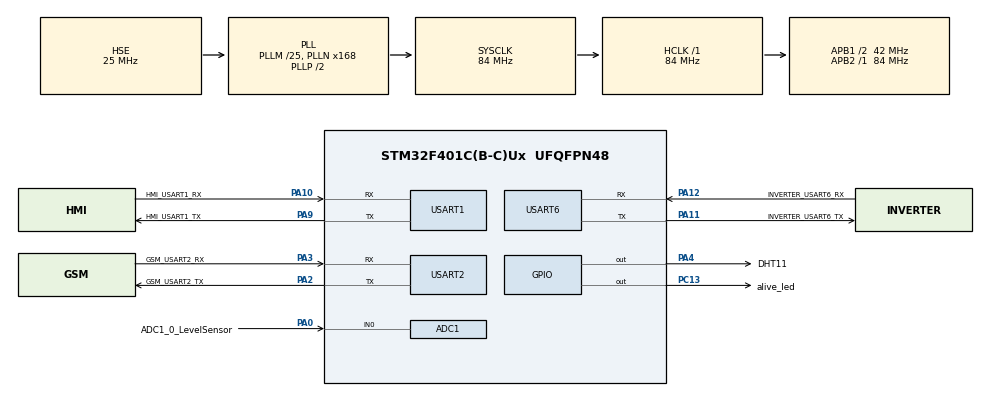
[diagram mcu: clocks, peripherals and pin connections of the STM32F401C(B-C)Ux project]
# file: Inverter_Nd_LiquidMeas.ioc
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ADC1.Channel-0\#ChannelRegularConversion=ADC_CHANNEL_0
ADC1.ContinuousConvMode=DISABLE
ADC1.NbrOfConversionFlag=1
ADC1.Rank-0\#ChannelRegularConversion=1
ADC1.SamplingTime-0\#ChannelRegularConversion=ADC_SAMPLETIME_480CYCLES
ADC1.master=1
FREERTOS.Tasks01=defaultTask,24,128,StartDefaultTask,Default,NULL,Dynamic,NULL,NULL
FREERTOS.configENABLE_FPU=1
FREERTOS.configTIMER_TASK_PRIORITY=55
FREERTOS.configTOTAL_HEAP_SIZE=30000
FREERTOS.configUSE_NEWLIB_REENTRANT=1
FREERTOS.configUSE_OS2_EVENTFLAGS_FROM_ISR=0
FREERTOS.configUSE_OS2_MUTEX=0
FREERTOS.configUSE_OS2_THREAD_ENUMERATE=0
FREERTOS.configUSE_OS2_THREAD_FLAGS=0
FREERTOS.configUSE_OS2_THREAD_SUSPEND_RESUME=0
FREERTOS.configUSE_OS2_TIMER=0
Mcu.Family=STM32F4
Mcu.Name=STM32F401C(B-C)Ux
Mcu.Package=UFQFPN48
Mcu.UserConstants=HMI_USART1,$$_USART1_IP_HANDLE_$$;INVERTER_USART6,$$_USART6_IP_HANDLE_$$;GSM_USART2,$$_USART2_IP_HANDLE_$$;DHT_Timer,$$_TIM11_IP_HANDLE_$$
NVIC.PriorityGroup=NVIC_PRIORITYGROUP_4
NVIC.TIM3_IRQn=true\:15\:0\:true\:false\:true\:false\:false\:true\:true
NVIC.TimeBase=TIM3_IRQn
NVIC.TimeBaseIP=TIM3
NVIC.USART1_IRQn=true\:5\:0\:false\:false\:true\:true\:true\:true\:true
NVIC.USART2_IRQn=true\:5\:0\:false\:false\:true\:true\:true\:true\:true
NVIC.USART6_IRQn=true\:5\:0\:false\:false\:true\:true\:true\:true\:true
PA0-WKUP.GPIO_Label=ADC1_0_LevelSensor
PA0-WKUP.Signal=ADCx_IN0
PA10.GPIO_Label=HMI_USART1_RX
PA10.Mode=Asynchronous
PA10.Signal=USART1_RX
PA11.GPIO_Label=INVERTER_USART6_TX
PA11.Mode=Asynchronous
PA11.Signal=USART6_TX
PA12.GPIO_Label=INVERTER_USART6_RX
PA12.Mode=Asynchronous
PA12.Signal=USART6_RX
PA2.GPIO_Label=GSM_USART2_TX
PA2.Mode=Asynchronous
PA2.Signal=USART2_TX
PA3.GPIO_Label=GSM_USART2_RX
PA3.Mode=Asynchronous
PA3.Signal=USART2_RX
PA4.GPIO_Label=DHT11
PA4.Signal=GPIO_Output
PA9.GPIO_Label=HMI_USART1_TX
PA9.Mode=Asynchronous
PA9.Signal=USART1_TX
PC13-ANTI_TAMP.GPIO_Label=alive_led
PC13-ANTI_TAMP.Signal=GPIO_Output
PC14-OSC32_IN.Mode=LSE-External-Oscillator
PC14-OSC32_IN.Signal=RCC_OSC32_IN
PC15-OSC32_OUT.Mode=LSE-External-Oscillator
PC15-OSC32_OUT.Signal=RCC_OSC32_OUT
PH0\ -\ OSC_IN.Mode=HSE-External-Oscillator
PH0\ -\ OSC_IN.Signal=RCC_OSC_IN
PH1\ -\ OSC_OUT.Mode=HSE-External-Oscillator
PH1\ -\ OSC_OUT.Signal=RCC_OSC_OUT
ProjectManager.HeapSize=0x200
ProjectManager.StackSize=0x400
ProjectManager.TargetToolchain=STM32CubeIDE
RCC.48MHZClocksFreq_Value=42000000
RCC.AHBFreq_Value=84000000
RCC.APB1CLKDivider=RCC_HCLK_DIV2
RCC.APB1Freq_Value=42000000
RCC.APB1TimFreq_Value=84000000
RCC.APB2Freq_Value=84000000
RCC.APB2TimFreq_Value=84000000
RCC.CortexFreq_Value=84000000
RCC.HCLKFreq_Value=84000000
RCC.HSE_VALUE=25000000
RCC.HSI_VALUE=16000000
RCC.PLLM=25
RCC.PLLN=168
RCC.PLLSourceVirtual=RCC_PLLSOURCE_HSE
RCC.SYSCLKFreq_VALUE=84000000
RCC.SYSCLKSource=RCC_SYSCLKSOURCE_PLLCLK
RCC.VCOOutputFreq_Value=168000000
SH.ADCx_IN0.0=ADC1_IN0,IN0
TIM11.Prescaler=84-1
USART1.VirtualMode=VM_ASYNC
USART2.VirtualMode=VM_ASYNC
USART6.VirtualMode=VM_ASYNC
VP_FREERTOS_VS_CMSIS_V2.Mode=CMSIS_V2
VP_SYS_VS_tim3.Mode=TIM3
VP_TIM11_VS_ClockSourceINT.Mode=Enable_Timer
board=custom

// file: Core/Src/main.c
/* USER CODE BEGIN Header */
/**
  ******************************************************************************
  * @file           : main.c
  * @brief          : Main program body
  ******************************************************************************
  * @attention
  *
  * Copyright (c) 2024 STMicroelectronics.
  * All rights reserved.
  *
  * This software is licensed under terms that can be found in the LICENSE file
  * in the root directory of this software component.
  * If no LICENSE file comes with this software, it is provided AS-IS.
  *
  ******************************************************************************
  */
/* USER CODE END Header */
#include "main.h"
#include "cmsis_os.h"
#include "adc.h"
#include "tim.h"
#include "usart.h"
#include "gpio.h"

void SystemClock_Config(void);
void MX_FREERTOS_Init(void);

int main(void)
{

  /* MCU Configuration--------------------------------------------------------*/

  /* Reset of all peripherals, Initializes the Flash interface and the Systick. */
  HAL_Init();

  /* Configure the system clock */
  SystemClock_Config();

  /* Initialize all configured peripherals */
  MX_GPIO_Init();
  MX_USART1_UART_Init();
  MX_USART2_UART_Init();
  MX_USART6_UART_Init();
  MX_TIM11_Init();
  MX_ADC1_Init();
  /* USER CODE BEGIN 2 */
#ifdef disable_auto
  /* USER CODE END 2 */

  /* Init scheduler */
  osKernelInitialize();

  /* Call init function for freertos objects (in cmsis_os2.c) */
  MX_FREERTOS_Init();

  /* Start scheduler */
  osKernelStart();

  /* We should never get here as control is now taken by the scheduler */

  /* Infinite loop */
  /* USER CODE BEGIN WHILE */
#endif
  MX_FREERTOS_Init();
  while (1)
  {
    /* USER CODE END WHILE */

  }
}

void SystemClock_Config(void)
{
  RCC_OscInitTypeDef RCC_OscInitStruct = {0};
  RCC_ClkInitTypeDef RCC_ClkInitStruct = {0};

  /** Configure the main internal regulator output voltage
  */
  __HAL_RCC_PWR_CLK_ENABLE();
  __HAL_PWR_VOLTAGESCALING_CONFIG(PWR_REGULATOR_VOLTAGE_SCALE2);

  /** Initializes the RCC Oscillators according to the specified parameters
  * in the RCC_OscInitTypeDef structure.
  */
  RCC_OscInitStruct.OscillatorType = RCC_OSCILLATORTYPE_HSE;
  RCC_OscInitStruct.HSEState = RCC_HSE_ON;
  RCC_OscInitStruct.PLL.PLLState = RCC_PLL_ON;
  RCC_OscInitStruct.PLL.PLLSource = RCC_PLLSOURCE_HSE;
  RCC_OscInitStruct.PLL.PLLM = 25;
  RCC_OscInitStruct.PLL.PLLN = 168;
  RCC_OscInitStruct.PLL.PLLP = RCC_PLLP_DIV2;
  RCC_OscInitStruct.PLL.PLLQ = 4;
  if (HAL_RCC_OscConfig(&RCC_OscInitStruct) != HAL_OK)
  {
    Error_Handler();
  }

  /** Initializes the CPU, AHB and APB buses clocks
  */
  RCC_ClkInitStruct.ClockType = RCC_CLOCKTYPE_HCLK|RCC_CLOCKTYPE_SYSCLK
                              |RCC_CLOCKTYPE_PCLK1|RCC_CLOCKTYPE_PCLK2;
  RCC_ClkInitStruct.SYSCLKSource = RCC_SYSCLKSOURCE_PLLCLK;
  RCC_ClkInitStruct.AHBCLKDivider = RCC_SYSCLK_DIV1;
  RCC_ClkInitStruct.APB1CLKDivider = RCC_HCLK_DIV2;
  RCC_ClkInitStruct.APB2CLKDivider = RCC_HCLK_DIV1;

  if (HAL_RCC_ClockConfig(&RCC_ClkInitStruct, FLASH_LATENCY_2) != HAL_OK)
  {
    Error_Handler();
  }
}

void HAL_TIM_PeriodElapsedCallback(TIM_HandleTypeDef *htim)
{
  if (htim->Instance == TIM3) {
    HAL_IncTick();
  }
}

void Error_Handler(void)
{
  __disable_irq();
  while (1)
  {
  }
}
